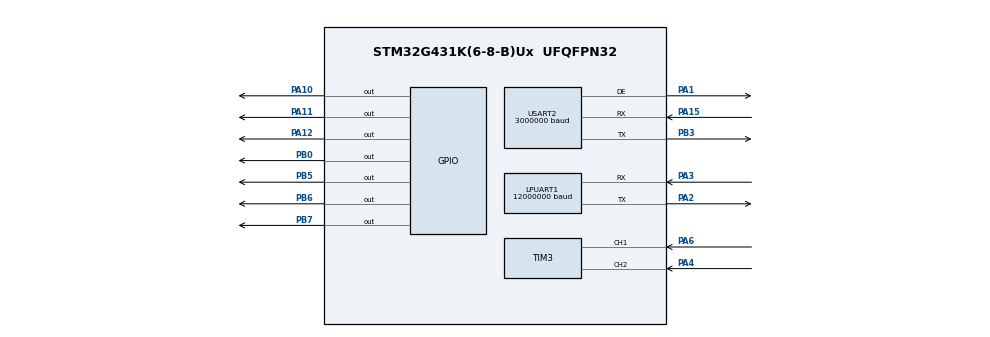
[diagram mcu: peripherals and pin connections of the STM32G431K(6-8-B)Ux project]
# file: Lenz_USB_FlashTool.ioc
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Dma.LPUART1_RX.0.Direction=DMA_PERIPH_TO_MEMORY
Dma.LPUART1_RX.0.EventEnable=DISABLE
Dma.LPUART1_RX.0.Instance=DMA1_Channel1
Dma.LPUART1_RX.0.MemDataAlignment=DMA_MDATAALIGN_BYTE
Dma.LPUART1_RX.0.MemInc=DMA_MINC_ENABLE
Dma.LPUART1_RX.0.Mode=DMA_CIRCULAR
Dma.LPUART1_RX.0.PeriphDataAlignment=DMA_PDATAALIGN_BYTE
Dma.LPUART1_RX.0.PeriphInc=DMA_PINC_DISABLE
Dma.LPUART1_RX.0.Polarity=HAL_DMAMUX_REQ_GEN_RISING
Dma.LPUART1_RX.0.Priority=DMA_PRIORITY_LOW
Dma.LPUART1_RX.0.RequestNumber=1
Dma.LPUART1_RX.0.SignalID=NONE
Dma.LPUART1_RX.0.SyncEnable=DISABLE
Dma.LPUART1_RX.0.SyncPolarity=HAL_DMAMUX_SYNC_NO_EVENT
Dma.LPUART1_RX.0.SyncRequestNumber=1
Dma.LPUART1_RX.0.SyncSignalID=NONE
Dma.LPUART1_TX.1.Direction=DMA_MEMORY_TO_PERIPH
Dma.LPUART1_TX.1.EventEnable=DISABLE
Dma.LPUART1_TX.1.Instance=DMA1_Channel2
Dma.LPUART1_TX.1.MemDataAlignment=DMA_MDATAALIGN_BYTE
Dma.LPUART1_TX.1.MemInc=DMA_MINC_ENABLE
Dma.LPUART1_TX.1.Mode=DMA_NORMAL
Dma.LPUART1_TX.1.PeriphDataAlignment=DMA_PDATAALIGN_BYTE
Dma.LPUART1_TX.1.PeriphInc=DMA_PINC_DISABLE
Dma.LPUART1_TX.1.Polarity=HAL_DMAMUX_REQ_GEN_RISING
Dma.LPUART1_TX.1.Priority=DMA_PRIORITY_LOW
Dma.LPUART1_TX.1.RequestNumber=1
Dma.LPUART1_TX.1.SignalID=NONE
Dma.LPUART1_TX.1.SyncEnable=DISABLE
Dma.LPUART1_TX.1.SyncPolarity=HAL_DMAMUX_SYNC_NO_EVENT
Dma.LPUART1_TX.1.SyncRequestNumber=1
Dma.LPUART1_TX.1.SyncSignalID=NONE
Dma.Request0=LPUART1_RX
Dma.Request1=LPUART1_TX
Dma.Request2=USART2_RX
Dma.USART2_RX.2.Direction=DMA_PERIPH_TO_MEMORY
Dma.USART2_RX.2.EventEnable=DISABLE
Dma.USART2_RX.2.Instance=DMA1_Channel5
Dma.USART2_RX.2.MemDataAlignment=DMA_MDATAALIGN_BYTE
Dma.USART2_RX.2.MemInc=DMA_MINC_ENABLE
Dma.USART2_RX.2.Mode=DMA_NORMAL
Dma.USART2_RX.2.PeriphDataAlignment=DMA_PDATAALIGN_BYTE
Dma.USART2_RX.2.PeriphInc=DMA_PINC_DISABLE
Dma.USART2_RX.2.Polarity=HAL_DMAMUX_REQ_GEN_RISING
Dma.USART2_RX.2.Priority=DMA_PRIORITY_LOW
Dma.USART2_RX.2.RequestNumber=1
Dma.USART2_RX.2.SignalID=NONE
Dma.USART2_RX.2.SyncEnable=DISABLE
Dma.USART2_RX.2.SyncPolarity=HAL_DMAMUX_SYNC_NO_EVENT
Dma.USART2_RX.2.SyncRequestNumber=1
Dma.USART2_RX.2.SyncSignalID=NONE
LPUART1.BaudRate=12000000
Mcu.Family=STM32G4
Mcu.Name=STM32G431K(6-8-B)Ux
Mcu.Package=UFQFPN32
NVIC.DMA1_Channel1_IRQn=true\:0\:0\:false\:false\:true\:false\:true\:true
NVIC.DMA1_Channel2_IRQn=true\:0\:0\:false\:false\:true\:false\:true\:true
NVIC.DMA1_Channel5_IRQn=true\:0\:0\:false\:false\:true\:false\:true\:true
NVIC.PriorityGroup=NVIC_PRIORITYGROUP_4
NVIC.TIM7_IRQn=true\:0\:0\:false\:false\:false\:true\:false\:true
PA0.Signal=ADC1_IN1
PA1.Mode=Hardware Flow Control (RS485)
PA1.Signal=USART2_DE
PA10.Signal=GPIO_Output
PA11.Signal=GPIO_Output
PA12.Signal=GPIO_Output
PA13.Mode=Serial_Wire
PA13.Signal=SYS_JTMS-SWDIO
PA14.Mode=Serial_Wire
PA14.Signal=SYS_JTCK-SWCLK
PA15.Mode=Asynchronous
PA15.Signal=USART2_RX
PA2.Mode=Asynchronous
PA2.Signal=LPUART1_TX
PA3.Mode=Asynchronous
PA3.Signal=LPUART1_RX
PA4.Signal=S_TIM3_CH2
PA6.Signal=S_TIM3_CH1
PA6.Stacked=true
PB0.Signal=GPIO_Output
PB3.Signal=SharedStack_PB3
PB3.Stacked=true
PB4.Signal=SPI3_MISO
PB5.Signal=GPIO_Output
PB6.Signal=GPIO_Output
PB7.Signal=GPIO_Output
PF0-OSC_IN.Mode=HSE-External-Oscillator
PF0-OSC_IN.Signal=RCC_OSC_IN
PF1-OSC_OUT.Mode=HSE-External-Oscillator
PF1-OSC_OUT.Signal=RCC_OSC_OUT
ProjectManager.HeapSize=0x200
ProjectManager.StackSize=0x400
ProjectManager.TargetToolchain=MDK-ARM V5.32
RCC.ADC12Freq_Value=144000000
RCC.AHBFreq_Value=144000000
RCC.APB1Freq_Value=144000000
RCC.APB1TimFreq_Value=144000000
RCC.APB2Freq_Value=144000000
RCC.APB2TimFreq_Value=144000000
RCC.CortexFreq_Value=144000000
RCC.EXTERNAL_CLOCK_VALUE=12288000
RCC.HCLKFreq_Value=144000000
RCC.HSE_VALUE=8000000
RCC.HSI48_VALUE=48000000
RCC.HSI_VALUE=16000000
RCC.LSE_VALUE=32768
RCC.PLLN=36
RCC.PLLSourceVirtual=RCC_PLLSOURCE_HSE
RCC.RCC_MCO1Source=RCC_MCO1SOURCE_HSE
RCC.RCC_MCODiv=RCC_MCODIV_16
RCC.SYSCLKFreq_VALUE=144000000
RCC.SYSCLKSource=RCC_SYSCLKSOURCE_PLLCLK
RCC.USBFreq_Value=144000000
RCC.VCOOutputFreq_Value=288000000
SH.S_TIM3_CH1.0=TIM3_CH1,Encoder_Interface
SH.S_TIM3_CH2.0=TIM3_CH2,Encoder_Interface
SH.SharedStack_PB3.0=SPI3_SCK
SH.SharedStack_PB3.1=USART2_TX,Asynchronous
TIM7.PeriodNoDither=4799
USART2.BaudRate=3000000
USART2.VirtualMode-Asynchronous=VM_ASYNC
USART2.VirtualMode-Hardware\ Flow\ Control\ (RS485)=VM_ASYNC
VP_CORDIC_VS_CORDIC.Mode=CORDIC_Activate
VP_SYS_VS_DBSignals.Mode=DisableDeadBatterySignals
VP_TIM7_VS_ClockSourceINT.Mode=Enable_Timer
board=custom

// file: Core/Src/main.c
/* USER CODE BEGIN Header */
/**
  ******************************************************************************
  * @file           : main.c
  * @brief          : Main program body
  ******************************************************************************
  * @attention
  *
  * Copyright (c) 2024 STMicroelectronics.
  * All rights reserved.
  *
  * This software is licensed under terms that can be found in the LICENSE file
  * in the root directory of this software component.
  * If no LICENSE file comes with this software, it is provided AS-IS.
  *
  ******************************************************************************
  */
/* USER CODE END Header */
#include "main.h"

/* USER CODE BEGIN Includes */

#include "biss_c_master_hal.h"
#include "uart.h"
/* USER CODE END Includes */

void SystemClock_Config(void);
static void MX_GPIO_Init(void);
static void MX_DMA_Init(void);
static void MX_CORDIC_Init(void);
static void MX_LPUART1_UART_Init(void);
static void MX_TIM7_Init(void);
static void MX_USART2_UART_Init(void);
static void MX_TIM3_Init(void);

int main(void)
{

  /* MCU Configuration--------------------------------------------------------*/

  /* Reset of all peripherals, Initializes the Flash interface and the Systick. */
  LL_APB2_GRP1_EnableClock(LL_APB2_GRP1_PERIPH_SYSCFG);
  LL_APB1_GRP1_EnableClock(LL_APB1_GRP1_PERIPH_PWR);

  /* System interrupt init*/
  NVIC_SetPriorityGrouping(NVIC_PRIORITYGROUP_4);

  /* SysTick_IRQn interrupt configuration */
  NVIC_SetPriority(SysTick_IRQn, NVIC_EncodePriority(NVIC_GetPriorityGrouping(),15, 0));

  /** Disable the internal Pull-Up in Dead Battery pins of UCPD peripheral
  */
  LL_PWR_DisableUCPDDeadBattery();

  /* Configure the system clock */
  SystemClock_Config();

  /* Initialize all configured peripherals */
  MX_GPIO_Init();
  MX_DMA_Init();
  MX_CORDIC_Init();
  MX_LPUART1_UART_Init();
  MX_TIM7_Init();
  MX_USART2_UART_Init();
  MX_TIM3_Init();
  /* USER CODE BEGIN 2 */
	/*
	LL_GPIO_ResetOutputPin(DE1_PIN);
	LL_GPIO_SetOutputPin(PWR1_EN_PIN);
	LL_TIM_EnableCounter(TIM_RENISHAW);
	uint32_t counter_value = 0;
	counter_value = LL_TIM_GetCounter(TIM_RENISHAW);
	*/
	InitRenishaw();
	InitUart();

	BiSS_C_Master_HAL_Init();

  /* USER CODE END 2 */

  /* Infinite loop */
  while (1)
  {

  }
}

void SystemClock_Config(void)
{
  LL_FLASH_SetLatency(LL_FLASH_LATENCY_4);
  while(LL_FLASH_GetLatency() != LL_FLASH_LATENCY_4)
  {
  }
  LL_PWR_SetRegulVoltageScaling(LL_PWR_REGU_VOLTAGE_SCALE1);
  LL_RCC_HSE_Enable();
   /* Wait till HSE is ready */
  while(LL_RCC_HSE_IsReady() != 1)
  {
  }

  LL_RCC_PLL_ConfigDomain_SYS(LL_RCC_PLLSOURCE_HSE, LL_RCC_PLLM_DIV_1, 36, LL_RCC_PLLR_DIV_2);
  LL_RCC_PLL_EnableDomain_SYS();
  LL_RCC_PLL_Enable();
   /* Wait till PLL is ready */
  while(LL_RCC_PLL_IsReady() != 1)
  {
  }

  LL_RCC_SetSysClkSource(LL_RCC_SYS_CLKSOURCE_PLL);
  LL_RCC_SetAHBPrescaler(LL_RCC_SYSCLK_DIV_2);
   /* Wait till System clock is ready */
  while(LL_RCC_GetSysClkSource() != LL_RCC_SYS_CLKSOURCE_STATUS_PLL)
  {
  }

  /* Insure 1us transition state at intermediate medium speed clock*/
  for (__IO uint32_t i = (170 >> 1); i !=0; i--);

  /* Set AHB prescaler*/
  LL_RCC_SetAHBPrescaler(LL_RCC_SYSCLK_DIV_1);
  LL_RCC_SetAPB1Prescaler(LL_RCC_APB1_DIV_1);
  LL_RCC_SetAPB2Prescaler(LL_RCC_APB2_DIV_1);

  LL_Init1msTick(144000000);

  LL_SetSystemCoreClock(144000000);
}

static void MX_CORDIC_Init(void)
{

  /* Peripheral clock enable */
  LL_AHB1_GRP1_EnableClock(LL_AHB1_GRP1_PERIPH_CORDIC);

  /* nothing else to be configured */

}

static void MX_LPUART1_UART_Init(void)
{

  LL_LPUART_InitTypeDef LPUART_InitStruct = {0};

  LL_GPIO_InitTypeDef GPIO_InitStruct = {0};

  LL_RCC_SetLPUARTClockSource(LL_RCC_LPUART1_CLKSOURCE_PCLK1);

  /* Peripheral clock enable */
  LL_APB1_GRP2_EnableClock(LL_APB1_GRP2_PERIPH_LPUART1);

  LL_AHB2_GRP1_EnableClock(LL_AHB2_GRP1_PERIPH_GPIOA);
  /**LPUART1 GPIO Configuration
  PA2   ------> LPUART1_TX
  PA3   ------> LPUART1_RX
  */
  GPIO_InitStruct.Pin = LL_GPIO_PIN_2;
  GPIO_InitStruct.Mode = LL_GPIO_MODE_ALTERNATE;
  GPIO_InitStruct.Speed = LL_GPIO_SPEED_FREQ_LOW;
  GPIO_InitStruct.OutputType = LL_GPIO_OUTPUT_PUSHPULL;
  GPIO_InitStruct.Pull = LL_GPIO_PULL_NO;
  GPIO_InitStruct.Alternate = LL_GPIO_AF_12;
  LL_GPIO_Init(GPIOA, &GPIO_InitStruct);

  GPIO_InitStruct.Pin = LL_GPIO_PIN_3;
  GPIO_InitStruct.Mode = LL_GPIO_MODE_ALTERNATE;
  GPIO_InitStruct.Speed = LL_GPIO_SPEED_FREQ_LOW;
  GPIO_InitStruct.OutputType = LL_GPIO_OUTPUT_PUSHPULL;
  GPIO_InitStruct.Pull = LL_GPIO_PULL_NO;
  GPIO_InitStruct.Alternate = LL_GPIO_AF_12;
  LL_GPIO_Init(GPIOA, &GPIO_InitStruct);

  /* LPUART1 DMA Init */

  /* LPUART1_RX Init */
  LL_DMA_SetPeriphRequest(DMA1, LL_DMA_CHANNEL_1, LL_DMAMUX_REQ_LPUART1_RX);

  LL_DMA_SetDataTransferDirection(DMA1, LL_DMA_CHANNEL_1, LL_DMA_DIRECTION_PERIPH_TO_MEMORY);

  LL_DMA_SetChannelPriorityLevel(DMA1, LL_DMA_CHANNEL_1, LL_DMA_PRIORITY_LOW);

  LL_DMA_SetMode(DMA1, LL_DMA_CHANNEL_1, LL_DMA_MODE_CIRCULAR);

  LL_DMA_SetPeriphIncMode(DMA1, LL_DMA_CHANNEL_1, LL_DMA_PERIPH_NOINCREMENT);

  LL_DMA_SetMemoryIncMode(DMA1, LL_DMA_CHANNEL_1, LL_DMA_MEMORY_INCREMENT);

  LL_DMA_SetPeriphSize(DMA1, LL_DMA_CHANNEL_1, LL_DMA_PDATAALIGN_BYTE);

  LL_DMA_SetMemorySize(DMA1, LL_DMA_CHANNEL_1, LL_DMA_MDATAALIGN_BYTE);

  /* LPUART1_TX Init */
  LL_DMA_SetPeriphRequest(DMA1, LL_DMA_CHANNEL_2, LL_DMAMUX_REQ_LPUART1_TX);

  LL_DMA_SetDataTransferDirection(DMA1, LL_DMA_CHANNEL_2, LL_DMA_DIRECTION_MEMORY_TO_PERIPH);

  LL_DMA_SetChannelPriorityLevel(DMA1, LL_DMA_CHANNEL_2, LL_DMA_PRIORITY_LOW);

  LL_DMA_SetMode(DMA1, LL_DMA_CHANNEL_2, LL_DMA_MODE_NORMAL);

  LL_DMA_SetPeriphIncMode(DMA1, LL_DMA_CHANNEL_2, LL_DMA_PERIPH_NOINCREMENT);

  LL_DMA_SetMemoryIncMode(DMA1, LL_DMA_CHANNEL_2, LL_DMA_MEMORY_INCREMENT);

  LL_DMA_SetPeriphSize(DMA1, LL_DMA_CHANNEL_2, LL_DMA_PDATAALIGN_BYTE);

  LL_DMA_SetMemorySize(DMA1, LL_DMA_CHANNEL_2, LL_DMA_MDATAALIGN_BYTE);

  LPUART_InitStruct.PrescalerValue = LL_LPUART_PRESCALER_DIV1;
  LPUART_InitStruct.BaudRate = 12000000;
  LPUART_InitStruct.DataWidth = LL_LPUART_DATAWIDTH_8B;
  LPUART_InitStruct.StopBits = LL_LPUART_STOPBITS_1;
  LPUART_InitStruct.Parity = LL_LPUART_PARITY_NONE;
  LPUART_InitStruct.TransferDirection = LL_LPUART_DIRECTION_TX_RX;
  LPUART_InitStruct.HardwareFlowControl = LL_LPUART_HWCONTROL_NONE;
  LL_LPUART_Init(LPUART1, &LPUART_InitStruct);
  LL_LPUART_SetTXFIFOThreshold(LPUART1, LL_LPUART_FIFOTHRESHOLD_1_8);
  LL_LPUART_SetRXFIFOThreshold(LPUART1, LL_LPUART_FIFOTHRESHOLD_1_8);
  LL_LPUART_DisableFIFO(LPUART1);

  LL_LPUART_Enable(LPUART1);

  /* Polling LPUART1 initialisation */
  while((!(LL_LPUART_IsActiveFlag_TEACK(LPUART1))) || (!(LL_LPUART_IsActiveFlag_REACK(LPUART1))))
  {
  }

}

static void MX_USART2_UART_Init(void)
{

  LL_USART_InitTypeDef USART_InitStruct = {0};

  LL_GPIO_InitTypeDef GPIO_InitStruct = {0};

  LL_RCC_SetUSARTClockSource(LL_RCC_USART2_CLKSOURCE_PCLK1);

  /* Peripheral clock enable */
  LL_APB1_GRP1_EnableClock(LL_APB1_GRP1_PERIPH_USART2);

  LL_AHB2_GRP1_EnableClock(LL_AHB2_GRP1_PERIPH_GPIOA);
  LL_AHB2_GRP1_EnableClock(LL_AHB2_GRP1_PERIPH_GPIOB);
  /**USART2 GPIO Configuration
  PA1   ------> USART2_DE
  PA15   ------> USART2_RX
  PB3   ------> USART2_TX
  */
  GPIO_InitStruct.Pin = LL_GPIO_PIN_1;
  GPIO_InitStruct.Mode = LL_GPIO_MODE_ALTERNATE;
  GPIO_InitStruct.Speed = LL_GPIO_SPEED_FREQ_LOW;
  GPIO_InitStruct.OutputType = LL_GPIO_OUTPUT_PUSHPULL;
  GPIO_InitStruct.Pull = LL_GPIO_PULL_NO;
  GPIO_InitStruct.Alternate = LL_GPIO_AF_7;
  LL_GPIO_Init(GPIOA, &GPIO_InitStruct);

  GPIO_InitStruct.Pin = LL_GPIO_PIN_15;
  GPIO_InitStruct.Mode = LL_GPIO_MODE_ALTERNATE;
  GPIO_InitStruct.Speed = LL_GPIO_SPEED_FREQ_LOW;
  GPIO_InitStruct.OutputType = LL_GPIO_OUTPUT_PUSHPULL;
  GPIO_InitStruct.Pull = LL_GPIO_PULL_NO;
  GPIO_InitStruct.Alternate = LL_GPIO_AF_7;
  LL_GPIO_Init(GPIOA, &GPIO_InitStruct);

  GPIO_InitStruct.Pin = LL_GPIO_PIN_3;
  GPIO_InitStruct.Mode = LL_GPIO_MODE_ALTERNATE;
  GPIO_InitStruct.Speed = LL_GPIO_SPEED_FREQ_LOW;
  GPIO_InitStruct.OutputType = LL_GPIO_OUTPUT_PUSHPULL;
  GPIO_InitStruct.Pull = LL_GPIO_PULL_NO;
  GPIO_InitStruct.Alternate = LL_GPIO_AF_7;
  LL_GPIO_Init(GPIOB, &GPIO_InitStruct);

  /* USART2 DMA Init */

  /* USART2_RX Init */
  LL_DMA_SetPeriphRequest(DMA1, LL_DMA_CHANNEL_5, LL_DMAMUX_REQ_USART2_RX);

  LL_DMA_SetDataTransferDirection(DMA1, LL_DMA_CHANNEL_5, LL_DMA_DIRECTION_PERIPH_TO_MEMORY);

  LL_DMA_SetChannelPriorityLevel(DMA1, LL_DMA_CHANNEL_5, LL_DMA_PRIORITY_LOW);

  LL_DMA_SetMode(DMA1, LL_DMA_CHANNEL_5, LL_DMA_MODE_NORMAL);

  LL_DMA_SetPeriphIncMode(DMA1, LL_DMA_CHANNEL_5, LL_DMA_PERIPH_NOINCREMENT);

  LL_DMA_SetMemoryIncMode(DMA1, LL_DMA_CHANNEL_5, LL_DMA_MEMORY_INCREMENT);

  LL_DMA_SetPeriphSize(DMA1, LL_DMA_CHANNEL_5, LL_DMA_PDATAALIGN_BYTE);

  LL_DMA_SetMemorySize(DMA1, LL_DMA_CHANNEL_5, LL_DMA_MDATAALIGN_BYTE);

  USART_InitStruct.PrescalerValue = LL_USART_PRESCALER_DIV1;
  USART_InitStruct.BaudRate = 3000000;
  USART_InitStruct.DataWidth = LL_USART_DATAWIDTH_8B;
  USART_InitStruct.StopBits = LL_USART_STOPBITS_1;
  USART_InitStruct.Parity = LL_USART_PARITY_NONE;
  USART_InitStruct.TransferDirection = LL_USART_DIRECTION_TX_RX;
  USART_InitStruct.HardwareFlowControl = LL_USART_HWCONTROL_NONE;
  USART_InitStruct.OverSampling = LL_USART_OVERSAMPLING_16;
  LL_USART_Init(USART2, &USART_InitStruct);
  LL_USART_SetTXFIFOThreshold(USART2, LL_USART_FIFOTHRESHOLD_1_8);
  LL_USART_SetRXFIFOThreshold(USART2, LL_USART_FIFOTHRESHOLD_1_8);
  LL_USART_EnableDEMode(USART2);
  LL_USART_SetDESignalPolarity(USART2, LL_USART_DE_POLARITY_HIGH);
  LL_USART_SetDEAssertionTime(USART2, 0);
  LL_USART_SetDEDeassertionTime(USART2, 0);
  LL_USART_DisableFIFO(USART2);
  LL_USART_ConfigAsyncMode(USART2);

  LL_USART_Enable(USART2);

  /* Polling USART2 initialisation */
  while((!(LL_USART_IsActiveFlag_TEACK(USART2))) || (!(LL_USART_IsActiveFlag_REACK(USART2))))
  {
  }

}

static void MX_TIM3_Init(void)
{

  LL_TIM_InitTypeDef TIM_InitStruct = {0};

  LL_GPIO_InitTypeDef GPIO_InitStruct = {0};

  /* Peripheral clock enable */
  LL_APB1_GRP1_EnableClock(LL_APB1_GRP1_PERIPH_TIM3);

  LL_AHB2_GRP1_EnableClock(LL_AHB2_GRP1_PERIPH_GPIOA);
  /**TIM3 GPIO Configuration
  PA4   ------> TIM3_CH2
  PA6   ------> TIM3_CH1
  */
  GPIO_InitStruct.Pin = LL_GPIO_PIN_4;
  GPIO_InitStruct.Mode = LL_GPIO_MODE_ALTERNATE;
  GPIO_InitStruct.Speed = LL_GPIO_SPEED_FREQ_LOW;
  GPIO_InitStruct.OutputType = LL_GPIO_OUTPUT_PUSHPULL;
  GPIO_InitStruct.Pull = LL_GPIO_PULL_NO;
  GPIO_InitStruct.Alternate = LL_GPIO_AF_2;
  LL_GPIO_Init(GPIOA, &GPIO_InitStruct);

  GPIO_InitStruct.Pin = LL_GPIO_PIN_6;
  GPIO_InitStruct.Mode = LL_GPIO_MODE_ALTERNATE;
  GPIO_InitStruct.Speed = LL_GPIO_SPEED_FREQ_LOW;
  GPIO_InitStruct.OutputType = LL_GPIO_OUTPUT_PUSHPULL;
  GPIO_InitStruct.Pull = LL_GPIO_PULL_NO;
  GPIO_InitStruct.Alternate = LL_GPIO_AF_2;
  LL_GPIO_Init(GPIOA, &GPIO_InitStruct);

  TIM_InitStruct.Prescaler = 0;
  TIM_InitStruct.CounterMode = LL_TIM_COUNTERMODE_UP;
  TIM_InitStruct.Autoreload = 65535;
  TIM_InitStruct.ClockDivision = LL_TIM_CLOCKDIVISION_DIV1;
  LL_TIM_Init(TIM3, &TIM_InitStruct);
  LL_TIM_DisableARRPreload(TIM3);
  LL_TIM_SetEncoderMode(TIM3, LL_TIM_ENCODERMODE_X2_TI1);
  LL_TIM_IC_SetActiveInput(TIM3, LL_TIM_CHANNEL_CH1, LL_TIM_ACTIVEINPUT_DIRECTTI);
  LL_TIM_IC_SetPrescaler(TIM3, LL_TIM_CHANNEL_CH1, LL_TIM_ICPSC_DIV1);
  LL_TIM_IC_SetFilter(TIM3, LL_TIM_CHANNEL_CH1, LL_TIM_IC_FILTER_FDIV1);
  LL_TIM_IC_SetPolarity(TIM3, LL_TIM_CHANNEL_CH1, LL_TIM_IC_POLARITY_RISING);
  LL_TIM_IC_SetActiveInput(TIM3, LL_TIM_CHANNEL_CH2, LL_TIM_ACTIVEINPUT_DIRECTTI);
  LL_TIM_IC_SetPrescaler(TIM3, LL_TIM_CHANNEL_CH2, LL_TIM_ICPSC_DIV1);
  LL_TIM_IC_SetFilter(TIM3, LL_TIM_CHANNEL_CH2, LL_TIM_IC_FILTER_FDIV1);
  LL_TIM_IC_SetPolarity(TIM3, LL_TIM_CHANNEL_CH2, LL_TIM_IC_POLARITY_RISING);
  LL_TIM_SetTriggerOutput(TIM3, LL_TIM_TRGO_RESET);
  LL_TIM_DisableMasterSlaveMode(TIM3);

}

static void MX_TIM7_Init(void)
{

  LL_TIM_InitTypeDef TIM_InitStruct = {0};

  /* Peripheral clock enable */
  LL_APB1_GRP1_EnableClock(LL_APB1_GRP1_PERIPH_TIM7);

  /* TIM7 interrupt Init */
  NVIC_SetPriority(TIM7_IRQn, NVIC_EncodePriority(NVIC_GetPriorityGrouping(),0, 0));
  NVIC_EnableIRQ(TIM7_IRQn);

  TIM_InitStruct.Prescaler = 0;
  TIM_InitStruct.CounterMode = LL_TIM_COUNTERMODE_UP;
  TIM_InitStruct.Autoreload = 4799;
  LL_TIM_Init(TIM7, &TIM_InitStruct);
  LL_TIM_DisableARRPreload(TIM7);
  LL_TIM_SetTriggerOutput(TIM7, LL_TIM_TRGO_RESET);
  LL_TIM_DisableMasterSlaveMode(TIM7);

}

static void MX_DMA_Init(void)
{

  /* Init with LL driver */
  /* DMA controller clock enable */
  LL_AHB1_GRP1_EnableClock(LL_AHB1_GRP1_PERIPH_DMAMUX1);
  LL_AHB1_GRP1_EnableClock(LL_AHB1_GRP1_PERIPH_DMA1);

  /* DMA interrupt init */
  /* DMA1_Channel1_IRQn interrupt configuration */
  NVIC_SetPriority(DMA1_Channel1_IRQn, NVIC_EncodePriority(NVIC_GetPriorityGrouping(),0, 0));
  NVIC_EnableIRQ(DMA1_Channel1_IRQn);
  /* DMA1_Channel2_IRQn interrupt configuration */
  NVIC_SetPriority(DMA1_Channel2_IRQn, NVIC_EncodePriority(NVIC_GetPriorityGrouping(),0, 0));
  NVIC_EnableIRQ(DMA1_Channel2_IRQn);
  /* DMA1_Channel5_IRQn interrupt configuration */
  NVIC_SetPriority(DMA1_Channel5_IRQn, NVIC_EncodePriority(NVIC_GetPriorityGrouping(),0, 0));
  NVIC_EnableIRQ(DMA1_Channel5_IRQn);

}

static void MX_GPIO_Init(void)
{
  LL_GPIO_InitTypeDef GPIO_InitStruct = {0};

  /* GPIO Ports Clock Enable */
  LL_AHB2_GRP1_EnableClock(LL_AHB2_GRP1_PERIPH_GPIOF);
  LL_AHB2_GRP1_EnableClock(LL_AHB2_GRP1_PERIPH_GPIOA);
  LL_AHB2_GRP1_EnableClock(LL_AHB2_GRP1_PERIPH_GPIOB);

  /**/
  LL_GPIO_ResetOutputPin(GPIOB, LL_GPIO_PIN_0);

  /**/
  LL_GPIO_ResetOutputPin(GPIOA, LL_GPIO_PIN_10);

  /**/
  LL_GPIO_ResetOutputPin(GPIOA, LL_GPIO_PIN_11);

  /**/
  LL_GPIO_ResetOutputPin(GPIOA, LL_GPIO_PIN_12);

  /**/
  LL_GPIO_ResetOutputPin(GPIOB, LL_GPIO_PIN_5);

  /**/
  LL_GPIO_ResetOutputPin(GPIOB, LL_GPIO_PIN_6);

  /**/
  LL_GPIO_ResetOutputPin(GPIOB, LL_GPIO_PIN_7);

  /**/
  GPIO_InitStruct.Pin = LL_GPIO_PIN_0;
  GPIO_InitStruct.Mode = LL_GPIO_MODE_ANALOG;
  GPIO_InitStruct.Pull = LL_GPIO_PULL_NO;
  LL_GPIO_Init(GPIOA, &GPIO_InitStruct);

  /**/
  GPIO_InitStruct.Pin = LL_GPIO_PIN_0;
  GPIO_InitStruct.Mode = LL_GPIO_MODE_OUTPUT;
  GPIO_InitStruct.Speed = LL_GPIO_SPEED_FREQ_LOW;
  GPIO_InitStruct.OutputType = LL_GPIO_OUTPUT_PUSHPULL;
  GPIO_InitStruct.Pull = LL_GPIO_PULL_NO;
  LL_GPIO_Init(GPIOB, &GPIO_InitStruct);

  /**/
  GPIO_InitStruct.Pin = LL_GPIO_PIN_10;
  GPIO_InitStruct.Mode = LL_GPIO_MODE_OUTPUT;
  GPIO_InitStruct.Speed = LL_GPIO_SPEED_FREQ_LOW;
  GPIO_InitStruct.OutputType = LL_GPIO_OUTPUT_PUSHPULL;
  GPIO_InitStruct.Pull = LL_GPIO_PULL_NO;
  LL_GPIO_Init(GPIOA, &GPIO_InitStruct);

  /**/
  GPIO_InitStruct.Pin = LL_GPIO_PIN_11;
  GPIO_InitStruct.Mode = LL_GPIO_MODE_OUTPUT;
  GPIO_InitStruct.Speed = LL_GPIO_SPEED_FREQ_LOW;
  GPIO_InitStruct.OutputType = LL_GPIO_OUTPUT_PUSHPULL;
  GPIO_InitStruct.Pull = LL_GPIO_PULL_NO;
  LL_GPIO_Init(GPIOA, &GPIO_InitStruct);

  /**/
  GPIO_InitStruct.Pin = LL_GPIO_PIN_12;
  GPIO_InitStruct.Mode = LL_GPIO_MODE_OUTPUT;
  GPIO_InitStruct.Speed = LL_GPIO_SPEED_FREQ_LOW;
  GPIO_InitStruct.OutputType = LL_GPIO_OUTPUT_PUSHPULL;
  GPIO_InitStruct.Pull = LL_GPIO_PULL_NO;
  LL_GPIO_Init(GPIOA, &GPIO_InitStruct);

  /**/
  GPIO_InitStruct.Pin = LL_GPIO_PIN_4;
  GPIO_InitStruct.Mode = LL_GPIO_MODE_ALTERNATE;
  GPIO_InitStruct.Speed = LL_GPIO_SPEED_FREQ_LOW;
  GPIO_InitStruct.OutputType = LL_GPIO_OUTPUT_PUSHPULL;
  GPIO_InitStruct.Pull = LL_GPIO_PULL_NO;
  GPIO_InitStruct.Alternate = LL_GPIO_AF_6;
  LL_GPIO_Init(GPIOB, &GPIO_InitStruct);

  /**/
  GPIO_InitStruct.Pin = LL_GPIO_PIN_5;
  GPIO_InitStruct.Mode = LL_GPIO_MODE_OUTPUT;
  GPIO_InitStruct.Speed = LL_GPIO_SPEED_FREQ_LOW;
  GPIO_InitStruct.OutputType = LL_GPIO_OUTPUT_PUSHPULL;
  GPIO_InitStruct.Pull = LL_GPIO_PULL_NO;
  LL_GPIO_Init(GPIOB, &GPIO_InitStruct);

  /**/
  GPIO_InitStruct.Pin = LL_GPIO_PIN_6;
  GPIO_InitStruct.Mode = LL_GPIO_MODE_OUTPUT;
  GPIO_InitStruct.Speed = LL_GPIO_SPEED_FREQ_LOW;
  GPIO_InitStruct.OutputType = LL_GPIO_OUTPUT_PUSHPULL;
  GPIO_InitStruct.Pull = LL_GPIO_PULL_NO;
  LL_GPIO_Init(GPIOB, &GPIO_InitStruct);

  /**/
  GPIO_InitStruct.Pin = LL_GPIO_PIN_7;
  GPIO_InitStruct.Mode = LL_GPIO_MODE_OUTPUT;
  GPIO_InitStruct.Speed = LL_GPIO_SPEED_FREQ_LOW;
  GPIO_InitStruct.OutputType = LL_GPIO_OUTPUT_PUSHPULL;
  GPIO_InitStruct.Pull = LL_GPIO_PULL_NO;
  LL_GPIO_Init(GPIOB, &GPIO_InitStruct);

}

void Error_Handler(void)
{
  __disable_irq();
  while (1)
  {
  }
}
